# GD32H71x_72x register map
File version: 1.0
CPU: CM7 r1p2, little endian, MPU, FPU, 4 interrupt priority bits
Registers are 32-bit, read-write, reset 0x0 unless marked. A register's access mark holds for its fields unless they carry their own. Offsets are from the block's base; [hi:lo] are bit positions; {n}, {i} and the like mark numbered series.

## TIMER1 — General-level0-timers
Base 0x40000000
Same registers: TIMER4 0x40000C00, TIMER22 0x4000E000, TIMER23 0x4000E400
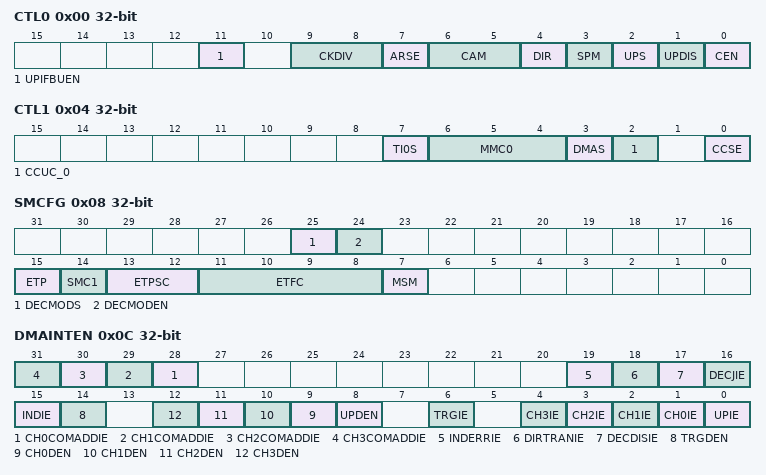
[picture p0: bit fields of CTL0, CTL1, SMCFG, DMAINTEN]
0x00 CTL0 — Control register 0
  [11] UPIFBUEN — UPIF bit backup enable
  [9:8] CKDIV — Clock division
  [7] ARSE — Auto-reload shadow enable
  [6:5] CAM — Counter align mode selection
  [4] DIR — Direction
  [3] SPM — Single pulse mode
  [2] UPS — Update source
  [1] UPDIS — Update disable
  [0] CEN — Counter enable
0x04 CTL1 — Control register 1
  [7] TI0S — Channel 0 trigger input selection
  [6:4] MMC0 — Master mode control 0
  [3] DMAS — DMA request source selection
  [2] CCUC_0 — Commutation control shadow register update control
  [0] CCSE — Commutation control shadow enable
0x08 SMCFG — Slave mode configuration register
  [25] DECMODS — Decoder mode update source
  [24] DECMODEN — Decoder mode modified on-the-fly enable
  [15] ETP — External trigger polarity
  [14] SMC1 — Part of slave mode controller is used to enable external clock mode 1
  [13:12] ETPSC — External trigger prescaler
  [11:8] ETFC — External trigger filter control
  [7] MSM — Master-slave mode
0x0C DMAINTEN — DMA and interrupt enable register
  [n+28] CH{n}COMADDIE (n=0..3) — Channel {n} additional compare interrupt enable
  [19] INDERRIE — Index error interrupt enable
  [18] DIRTRANIE — Direction transform interrupt enable
  [17] DECDISIE — Quadrature decoder signal disconnection interrupt enable
  [16] DECJIE — Quadrature decoder signal jump (the two signals jump at the same time) interrupt enable
  [15] INDIE — Index interrupt enable
  [14] TRGDEN — Trigger DMA request enable
  [n+9] CH{n}DEN (n=0..3) — Channel {n} capture/compare DMA request enable
  [8] UPDEN — Update DMA request enable
  [6] TRGIE — Trigger interrupt enable
  [n+1] CH{n}IE (n=0..3) — Channel {n} capture/compare interrupt enable
  [0] UPIE — Update interrupt enable
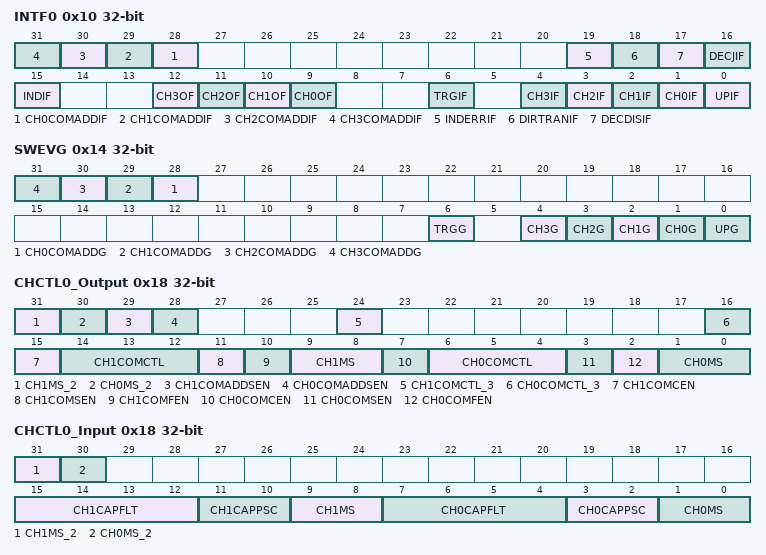
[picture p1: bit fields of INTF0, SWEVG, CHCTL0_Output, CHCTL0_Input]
0x10 INTF0 — Interrupt flag register 0
  [n+28] CH{n}COMADDIF (n=0..3) — Channel {n} additional compare interrupt flag.
  [19] INDERRIF — Index error interrupt flag
  [18] DIRTRANIF — Direction transform interrupt flag
  [17] DECDISIF — Quadrature decoder signal disconnection interrupt flag
  [16] DECJIF — Quadrature decoder signal jump (the two signals jump at the same time) interrupt flag
  [15] INDIF — Index interrupt flag
  [n+9] CH{n}OF (n=0..3) — Channel {n} over capture flag
  [6] TRGIF — Trigger interrupt flag
  [n+1] CH{n}IF (n=0..3) — Channel {n} capture/compare interrupt flag
  [0] UPIF — Update interrupt flag
0x14 SWEVG wo — Software event generation register
  [n+28] CH{n}COMADDG (n=0..3) — Channel {n} additional compare event generation
  [6] TRGG — Trigger event generation
  [n+1] CH{n}G (n=0..3) — Channel {n} capture or compare event generation
  [0] UPG — Update event generation
0x18 CHCTL0_Output — Channel control register 0 (output mode)
  [31] CH1MS_2 — 2th bit of CH1MS
  [30] CH0MS_2 — 2th bit of CH0MS
  [29] CH1COMADDSEN — Channel 1 additional compare output shadow enable
  [28] CH0COMADDSEN — Channel 0 additional compare output shadow enable
  [24] CH1COMCTL_3 — Bit 3 of channel 1 compare output control
  [16] CH0COMCTL_3 — Bit 3 of channel 1 compare output control
  [15] CH1COMCEN — Channel 1 output compare clear enable
  [14:12] CH1COMCTL — Channel 1 compare output control
  [11] CH1COMSEN — Channel 1 output compare shadow enable
  [10] CH1COMFEN — Channel 1 output compare fast enable
  [9:8] CH1MS — Channel 1 mode selection
  [7] CH0COMCEN — Channel 0 output compare clear enable
  [6:4] CH0COMCTL — Channel 0 compare output control
  [3] CH0COMSEN — Channel 0 compare output shadow enable
  [2] CH0COMFEN — Channel 0 output compare fast enable
  [1:0] CH0MS — Channel 0 I/O mode selection
0x18 CHCTL0_Input (alternate view of CHCTL0_Output) — Channel control register 0 (input mode)
  [31] CH1MS_2 — 2th bit of CH1MS
  [30] CH0MS_2 — 2th bit of CH0MS
  [15:12] CH1CAPFLT — Channel 1 input capture filter control
  [11:10] CH1CAPPSC — Channel 1 input capture prescaler
  [9:8] CH1MS — Channel 1 mode selection
  [7:4] CH0CAPFLT — Channel 0 input capture filter control
  [3:2] CH0CAPPSC — Channel 0 input capture prescaler
  [1:0] CH0MS — Channel 0 mode selection
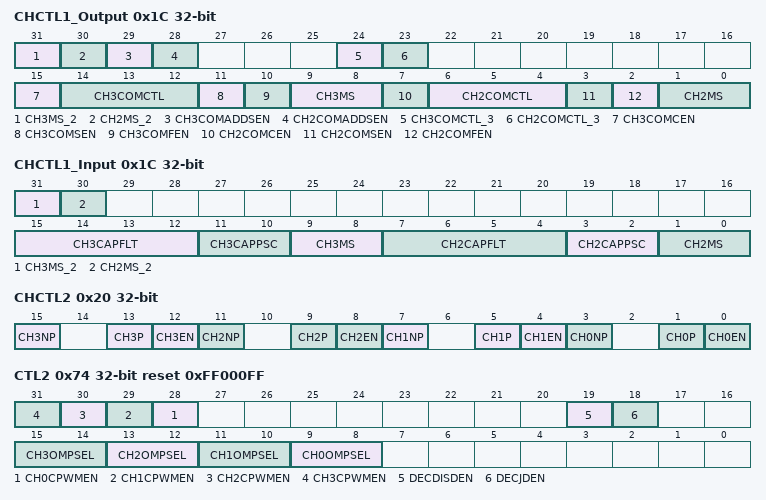
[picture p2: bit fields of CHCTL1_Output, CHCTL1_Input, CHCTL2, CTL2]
0x1C CHCTL1_Output — Channel control register 1 (output mode)
  [31] CH3MS_2 — 2th bit of CH3MS
  [30] CH2MS_2 — 2th bit of CH2MS
  [29] CH3COMADDSEN — Channel 3 additional compare output shadow enable
  [28] CH2COMADDSEN — Channel 2 additional compare output shadow enable
  [24] CH3COMCTL_3 — BIT 3 of channel 3 compare output control
  [23] CH2COMCTL_3 — BIT 3 of channel 2 compare output control
  [15] CH3COMCEN — Channel 3 output compare clear enable
  [14:12] CH3COMCTL — Channel 3 compare output control
  [11] CH3COMSEN — Channel 3 output compare shadow enable
  [10] CH3COMFEN — Channel 3 output compare fast enable
  [9:8] CH3MS — Channel 3 mode selection
  [7] CH2COMCEN — Channel 2 output compare clear enable
  [6:4] CH2COMCTL — Channel 2 compare output control
  [3] CH2COMSEN — Channel 2 compare output shadow enable
  [2] CH2COMFEN — Channel 2 output compare fast enable
  [1:0] CH2MS — Channel 2 I/O mode selection
0x1C CHCTL1_Input (alternate view of CHCTL1_Output) — Channel control register 1 (input mode)
  [31] CH3MS_2 — 2th bit of CH3MS
  [30] CH2MS_2 — 2th bit of CH2MS
  [15:12] CH3CAPFLT — Channel 3 input capture filter control
  [11:10] CH3CAPPSC — Channel 3 input capture prescaler
  [9:8] CH3MS — Channel 3 mode selection
  [7:4] CH2CAPFLT — Channel 2 input capture filter control
  [3:2] CH2CAPPSC — Channel 2 input capture prescaler
  [1:0] CH2MS — Channel 2 mode selection
0x20 CHCTL2 — Channel control register 2
  [15] CH3NP — Multi mode channel 3 capture/compare polarity
  [4n+1] CH{n}P (n=0..3) — Channel {n} capture/compare function polarity
  [4n] CH{n}EN (n=0..3) — Channel {n} capture/compare function enable
  [11] CH2NP — Multi mode channel 2 capture/compare polarity
  [7] CH1NP — Multi mode channel 1 output polarity
  [3] CH0NP — Multi mode channel 0 output polarity
0x24 CNT — counter
  [31:0] CNT — current counter value
0x28 PSC — prescaler
  [15:0] PSC — Prescaler value of the counter clock
0x2C CAR — Counter auto reload register
  [31:0] CARL — Counter auto reload value
0x34 CH0CV — Channel 0 capture/compare value register
  [31:0] CH0VAL — Capture or compare value of channel0
0x38 CH1CV — Channel 1 capture/compare value register
  [31:0] CH1VAL — Capture or compare value of channel1
0x3C CH2CV — Channel 2 capture/compare value register
  [31:0] CH2VAL — Capture or compare value of channel 2
0x40 CH3CV — Channel 3 capture/compare value register
  [31:0] CH3VAL — Capture or compare value of channel 3
{0x64+4i} CH{i}COMV_ADD (i=0..3) — Channel {i} additional compare value register
  [31:0] CH{i}COMVAL_ADD — Additional compare value of channel {i}
0x74 CTL2 reset 0xFF000FF — Control register 2
  [n+28] CH{n}CPWMEN (n=0..3) — Channel {n} composite PWM mode enable
  [19] DECDISDEN — Quadrature decoder signal disconnection detection enable
  [18] DECJDEN — Quadrature decoder signal jump detection enable
  [2n+9:2n+8] CH{n}OMPSEL (n=0..3) — Channel {n} output match pulse select
0x94 WDGPER — Watchdog counter register
  [31:0] WDGPER — Watchdog timeout count
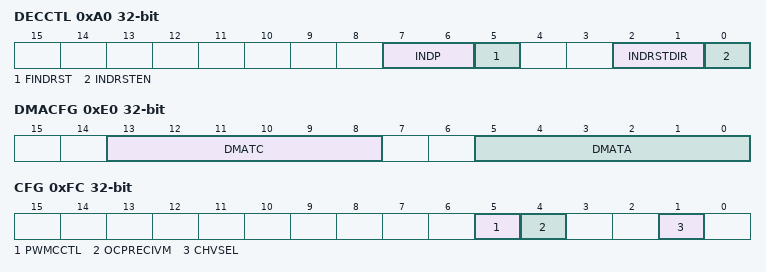
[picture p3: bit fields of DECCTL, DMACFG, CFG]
0xA0 DECCTL — Decoder control register
  [7:6] INDP — Index positioning
  [5] FINDRST — First index signal reset the counter
  [2:1] INDRSTDIR — Index signal reset counter direction
  [0] INDRSTEN — Index signal reset enable
0xE0 DMACFG — DMA configuration register
  [13:8] DMATC — DMA transfer count
  [5:0] DMATA — DMA transfer access start address
0xE4 DMATB — DMA transfer buffer register
  [31:0] DMATB — DMA transfer buffer
0xFC CFG — Configuration register
  [5] PWMCCTL — PWM mode change control
  [4] OCPRECIVM — Output prepare signal clear invalid mode select
  [1] CHVSEL — Write CHxVAL register selection bit

## TIMER2 — General-level0-timers
Base 0x40000400
Same registers: TIMER3 0x40000800, TIMER30 0x4000E800, TIMER31 0x4000EC00
Registers as TIMER1; these are added or differ:
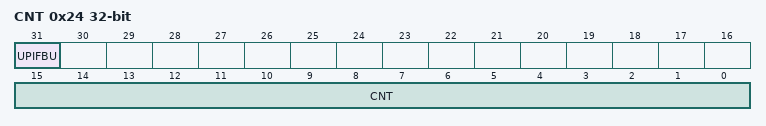
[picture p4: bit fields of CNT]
0x24 CNT access per field — counter
  [31] UPIFBU ro — UPIF bit backup
  [15:0] CNT rw — current counter value
